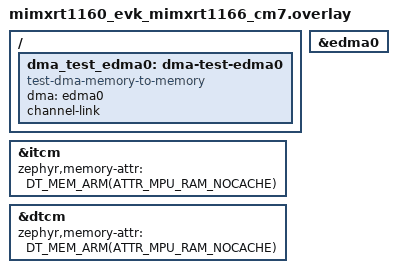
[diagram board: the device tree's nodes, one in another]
/*
 * Copyright (c) 2022 Kumar Gala <galak@kernel.org>
 * Copyright (c) 2024 NXP
 *
 * SPDX-License-Identifier: Apache-2.0
 */

#include <zephyr/dt-bindings/memory-attr/memory-attr-arm.h>

/ {
	dma_test_edma0: dma-test-edma0 {
		compatible = "test-dma-memory-to-memory";
		dma = <&edma0>;
		channel-link;
	};
};

&itcm {
	zephyr,memory-attr = <DT_MEM_ARM(ATTR_MPU_RAM_NOCACHE)>;
};

&edma0 {
	status = "okay";
};

&dtcm {
	zephyr,memory-attr = <DT_MEM_ARM(ATTR_MPU_RAM_NOCACHE)>;
};
